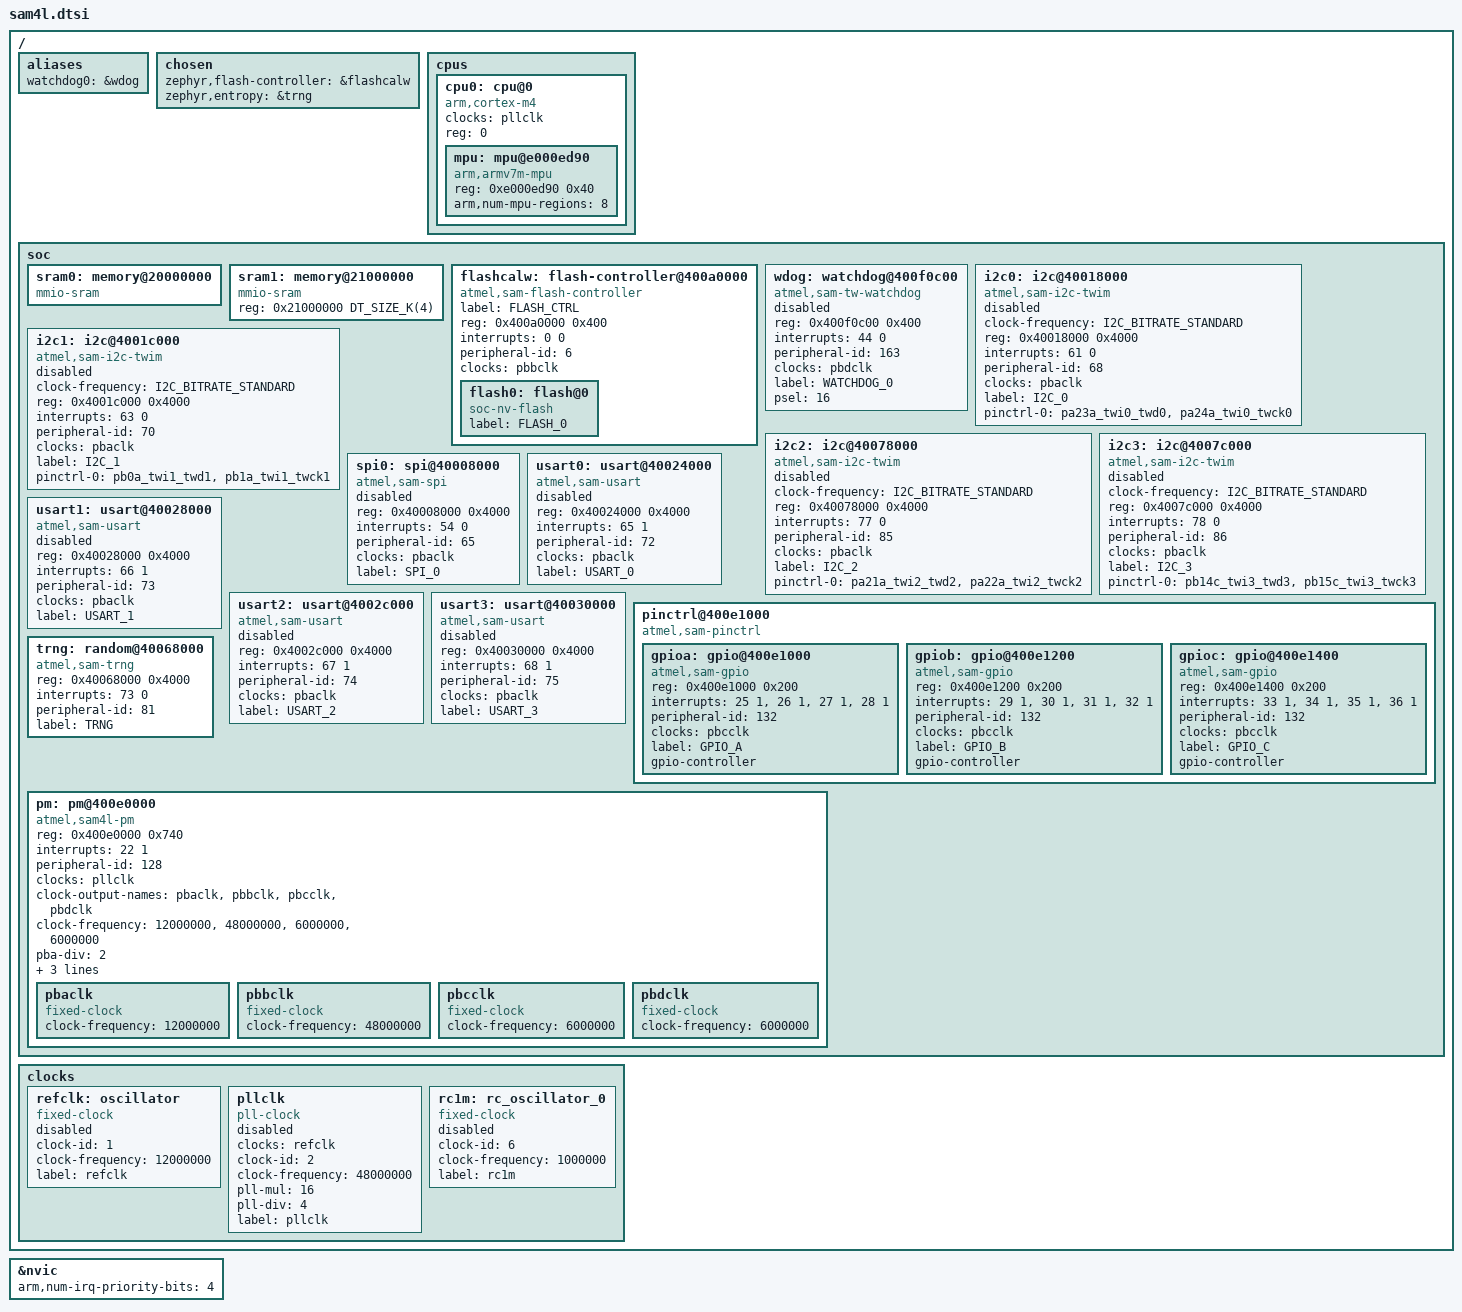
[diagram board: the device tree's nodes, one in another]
/*
 * Copyright (c) 2020 Gerson Fernando Budke <nandojve@gmail.com>
 *
 * SPDX-License-Identifier: Apache-2.0
 */

#include <arm/armv7-m.dtsi>
#include <dt-bindings/i2c/i2c.h>
#include <dt-bindings/gpio/gpio.h>

#include "sam4l-pinctrl.dtsi"

/ {
	aliases {
		watchdog0 = &wdog;
	};

	chosen {
		zephyr,flash-controller = &flashcalw;
		zephyr,entropy = &trng;
	};

	cpus {
		#address-cells = <1>;
		#size-cells = <0>;

		cpu0: cpu@0 {
			device_type = "cpu";
			compatible = "arm,cortex-m4";
			clocks = <&pllclk>;
			reg = <0>;
			#address-cells = <1>;
			#size-cells = <1>;

			mpu: mpu@e000ed90 {
				compatible = "arm,armv7m-mpu";
				reg = <0xe000ed90 0x40>;
				arm,num-mpu-regions = <8>;
			};
		};
	};

	soc {
		sram0: memory@20000000 {
			compatible = "mmio-sram";
		};
		/**
		 * HRAM1 are 4k SRAM that can be used by PicoCache or
		 * just extra memory available. The PicoCache will be
		 * keep disable to ensures deterministic behaviour. That
		 * way the extra memory can be exclusive for USB descriptors
		 */
		sram1: memory@21000000 {
			compatible = "mmio-sram";
			reg = <0x21000000 DT_SIZE_K(4)>;
		};

		flashcalw: flash-controller@400a0000 {
			compatible = "atmel,sam-flash-controller";
			label = "FLASH_CTRL";
			reg = <0x400a0000 0x400>;
			interrupts = <0 0>;
			peripheral-id = <6>;
			clocks = <&pbbclk>;
			#address-cells = <1>;
			#size-cells = <1>;

			flash0: flash@0 {
				compatible = "soc-nv-flash";
				label = "FLASH_0";
			};
		};

		wdog: watchdog@400f0c00 {
			compatible = "atmel,sam-tw-watchdog";
			reg = <0x400f0c00 0x400>;
			interrupts = <44 0>;
			peripheral-id = <163>;
			clocks = <&pbdclk>;
			label = "WATCHDOG_0";
			psel = <16>;
			status = "disabled";
		};

		i2c0: i2c@40018000 {
			compatible = "atmel,sam-i2c-twim";
			clock-frequency = <I2C_BITRATE_STANDARD>;
			reg = <0x40018000 0x4000>;
			interrupts = <61 0>;
			peripheral-id = <68>;
			clocks = <&pbaclk>;
			label = "I2C_0";
			status = "disabled";
			#address-cells = <1>;
			#size-cells = <0>;
			pinctrl-0 = <&pa23a_twi0_twd0 &pa24a_twi0_twck0>;
		};
		i2c1: i2c@4001c000 {
			compatible = "atmel,sam-i2c-twim";
			clock-frequency = <I2C_BITRATE_STANDARD>;
			reg = <0x4001c000 0x4000>;
			interrupts = <63 0>;
			peripheral-id = <70>;
			clocks = <&pbaclk>;
			label = "I2C_1";
			status = "disabled";
			#address-cells = <1>;
			#size-cells = <0>;
			pinctrl-0 = <&pb0a_twi1_twd1 &pb1a_twi1_twck1>;
		};
		i2c2: i2c@40078000 {
			compatible = "atmel,sam-i2c-twim";
			clock-frequency = <I2C_BITRATE_STANDARD>;
			reg = <0x40078000 0x4000>;
			interrupts = <77 0>;
			peripheral-id = <85>;
			clocks = <&pbaclk>;
			label = "I2C_2";
			status = "disabled";
			#address-cells = <1>;
			#size-cells = <0>;
			pinctrl-0 = <&pa21a_twi2_twd2 &pa22a_twi2_twck2>;
		};
		i2c3: i2c@4007c000 {
			compatible = "atmel,sam-i2c-twim";
			clock-frequency = <I2C_BITRATE_STANDARD>;
			reg = <0x4007c000 0x4000>;
			interrupts = <78 0>;
			peripheral-id = <86>;
			clocks = <&pbaclk>;
			label = "I2C_3";
			status = "disabled";
			#address-cells = <1>;
			#size-cells = <0>;
			pinctrl-0 = <&pb14c_twi3_twd3 &pb15c_twi3_twck3>;
		};

		spi0: spi@40008000 {
			compatible = "atmel,sam-spi";
			reg = <0x40008000 0x4000>;
			interrupts = <54 0>;
			peripheral-id = <65>;
			clocks = <&pbaclk>;
			label = "SPI_0";
			status = "disabled";
			#address-cells = <1>;
			#size-cells = <0>;
		};

		usart0: usart@40024000 {
			compatible = "atmel,sam-usart";
			reg = <0x40024000 0x4000>;
			interrupts = <65 1>;
			peripheral-id = <72>;
			clocks = <&pbaclk>;
			status = "disabled";
			label = "USART_0";
		};
		usart1: usart@40028000 {
			compatible = "atmel,sam-usart";
			reg = <0x40028000 0x4000>;
			interrupts = <66 1>;
			peripheral-id = <73>;
			clocks = <&pbaclk>;
			status = "disabled";
			label = "USART_1";
		};
		usart2: usart@4002c000 {
			compatible = "atmel,sam-usart";
			reg = <0x4002c000 0x4000>;
			interrupts = <67 1>;
			peripheral-id = <74>;
			clocks = <&pbaclk>;
			status = "disabled";
			label = "USART_2";
		};
		usart3: usart@40030000 {
			compatible = "atmel,sam-usart";
			reg = <0x40030000 0x4000>;
			interrupts = <68 1>;
			peripheral-id = <75>;
			clocks = <&pbaclk>;
			status = "disabled";
			label = "USART_3";
		};

		pinctrl@400e1000 {
			compatible = "atmel,sam-pinctrl";
			#address-cells = <1>;
			#size-cells = <1>;
			ranges = <0x400e1000 0x400e1000 0x800>;

			gpioa: gpio@400e1000 {
				compatible = "atmel,sam-gpio";
				reg = <0x400e1000 0x200>;
				interrupts = <25 1>, <26 1>, <27 1>, <28 1>;
				peripheral-id = <132>;
				clocks = <&pbcclk>;
				label = "GPIO_A";
				gpio-controller;
				#gpio-cells = <2>;
				#atmel,pin-cells = <2>;
			};
			gpiob: gpio@400e1200 {
				compatible = "atmel,sam-gpio";
				reg = <0x400e1200 0x200>;
				interrupts = <29 1>, <30 1>, <31 1>, <32 1>;
				peripheral-id = <132>;
				clocks = <&pbcclk>;
				label = "GPIO_B";
				gpio-controller;
				#gpio-cells = <2>;
				#atmel,pin-cells = <2>;
			};
			gpioc: gpio@400e1400 {
				compatible = "atmel,sam-gpio";
				reg = <0x400e1400 0x200>;
				interrupts = <33 1>, <34 1>, <35 1>, <36 1>;
				peripheral-id = <132>;
				clocks = <&pbcclk>;
				label = "GPIO_C";
				gpio-controller;
				#gpio-cells = <2>;
				#atmel,pin-cells = <2>;
			};
		};

		trng: random@40068000 {
			compatible = "atmel,sam-trng";
			reg = <0x40068000 0x4000>;
			interrupts = <73 0>;
			peripheral-id = <81>;
			status = "okay";
			label = "TRNG";
		};

		pm: pm@400e0000 {
			compatible = "atmel,sam4l-pm";
			reg = <0x400e0000 0x740>;
			interrupts = <22 1>;
			peripheral-id = <128>;
			clocks = <&pllclk>;
			#clock-cells = <1>;

			clock-output-names = "pbaclk", "pbbclk",
					     "pbcclk", "pbdclk";

			clock-frequency  = <12000000>, <48000000>,
					   <6000000>, <6000000>;

			/* pbXclk = pllclk / 2^(pbX-div) */
			pba-div = <2>;	/* pllclk / 4 */
			pbb-div = <0>;	/* pllclk */
			pbc-div = <3>;	/* pllclk / 8 */
			pbd-div = <3>;

			pbaclk: pbaclk {
				compatible = "fixed-clock";
				#clock-cells = <0>;
				clock-frequency = <12000000>;
			};

			pbbclk: pbbclk {
				compatible = "fixed-clock";
				#clock-cells = <0>;
				clock-frequency = <48000000>;
			};

			pbcclk: pbcclk {
				compatible = "fixed-clock";
				#clock-cells = <0>;
				clock-frequency = <6000000>;
			};

			pbdclk: pbdclk {
				compatible = "fixed-clock";
				#clock-cells = <0>;
				clock-frequency = <6000000>;
			};
		};
	};

	clocks {
		/* 12 MHz reference crystal */
		refclk: oscillator {
			compatible = "fixed-clock";
			#clock-cells = <0>;
			clock-id = <1>;
			clock-frequency = <12000000>;
			label = "refclk";
			status = "disabled";
		};

		/* 48 MHz fixed main PLL */
		pllclk: pllclk {
			compatible = "pll-clock";
			#clock-cells = <0>;
			clocks = <&refclk>;

			clock-id = <2>;
			clock-frequency = <48000000>;
			pll-mul = <16>;
			pll-div = <4>;
			label = "pllclk";
			status = "disabled";
		};

		/* 1 MHz RC oscillator */
		rc1m: rc_oscillator_0 {
			compatible = "fixed-clock";
			#clock-cells = <0>;
			clock-id = <6>;
			clock-frequency = <1000000>;
			label = "rc1m";
			status = "disabled";
		};
	};
};

&nvic {
	arm,num-irq-priority-bits = <4>;
};
